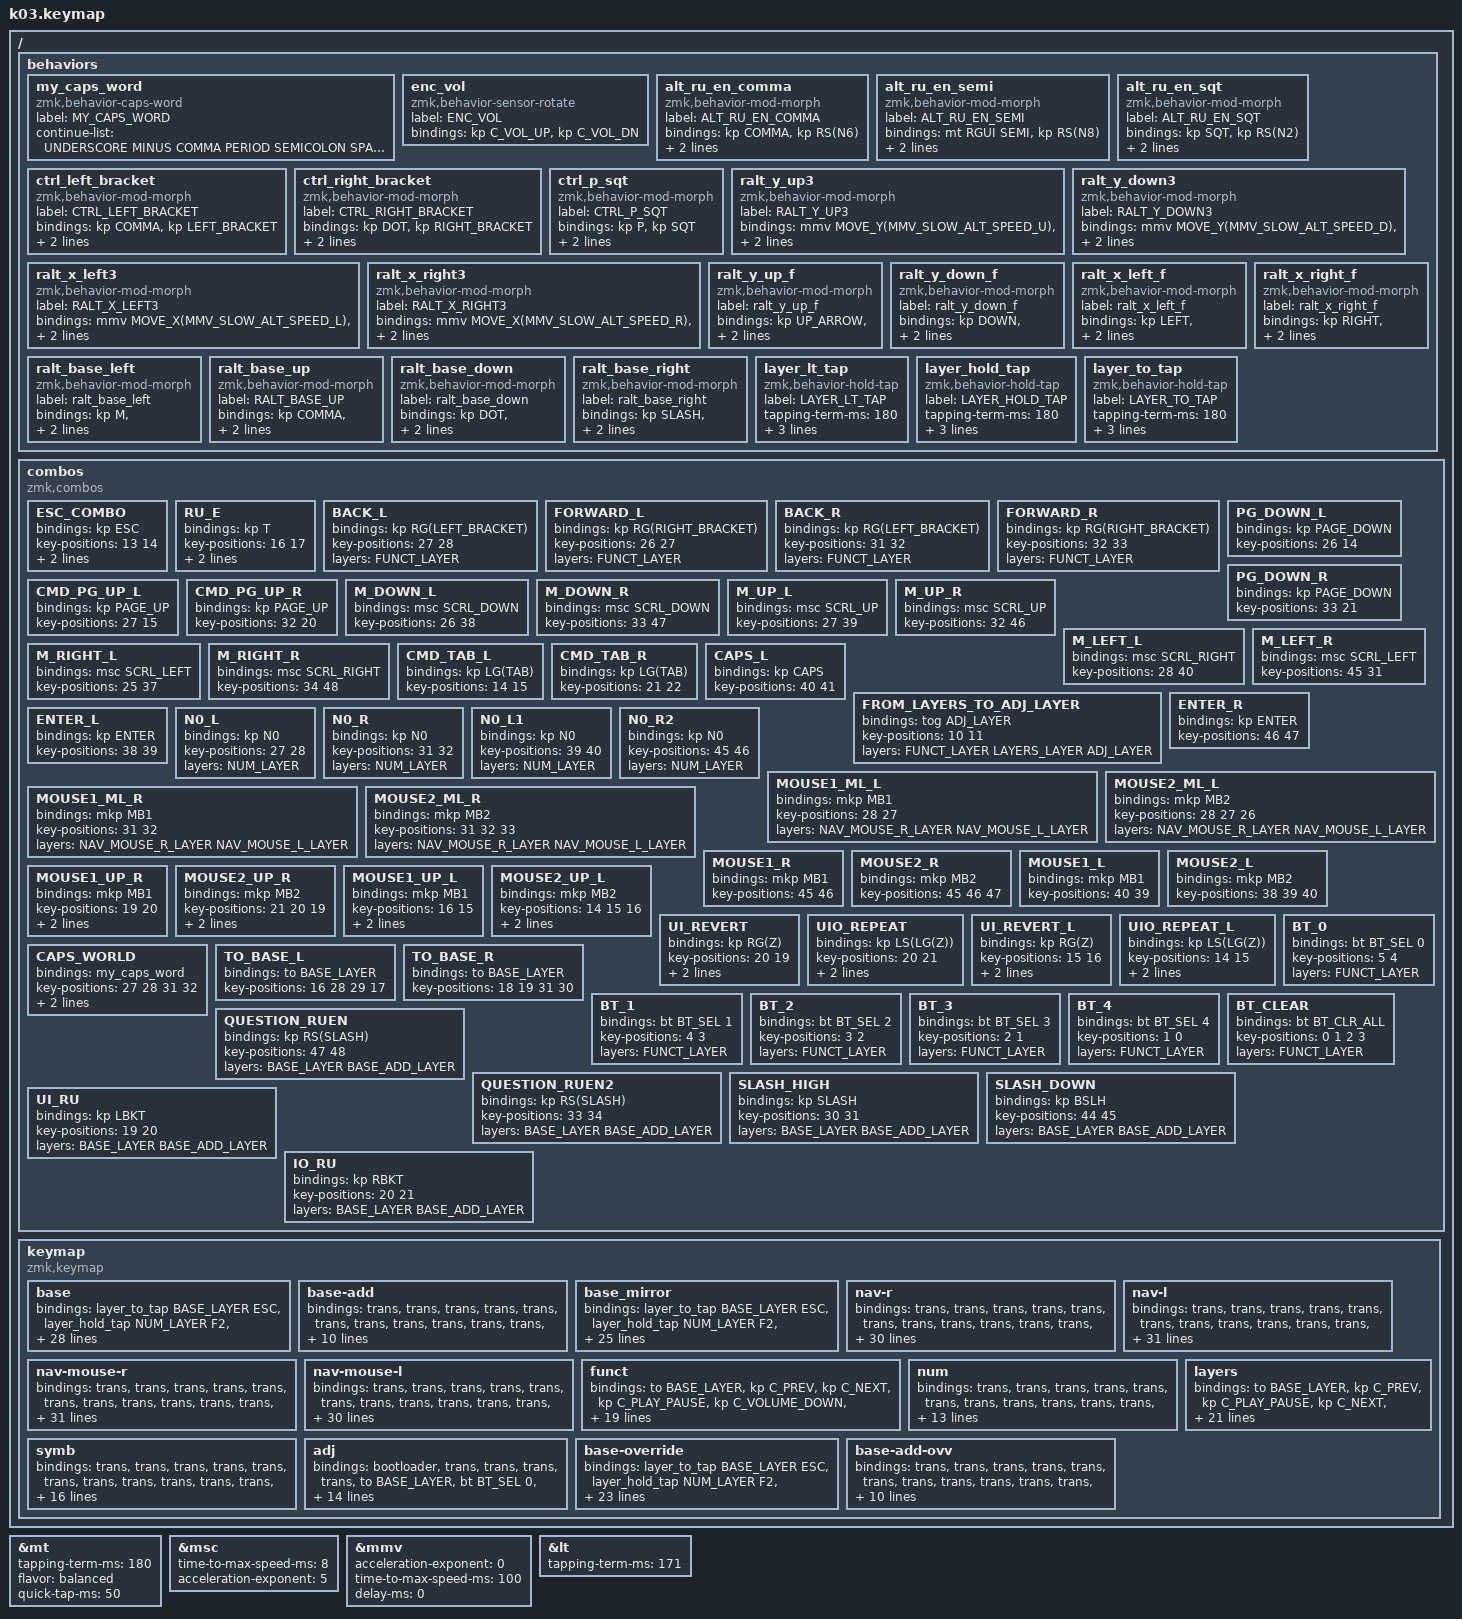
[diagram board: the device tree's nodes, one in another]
#define ZMK_POINTING_DEFAULT_SCRL_VAL 25

// Константы для перемещений

#define BASE_LAYER 0
#define BASE_ADD_LAYER 1
#define BASE_MIRROR_LAYER 2
#define NAV_R_LAYER 3
#define NAV_L_LAYER 4
#define NAV_MOUSE_R_LAYER 5
#define NAV_MOUSE_L_LAYER 6
#define FUNCT_LAYER 7
#define NUM_LAYER 8
#define SYMB_LAYER 9
#define LAYERS_LAYER 10
#define ADJ_LAYER 11
#define BASE_OVERRIDE_LAYER 12
#define BASE_ADD_OVERRIDE_LAYER 13

#define MMV_SLOW_ALT_SPEED 250
#define MMV_SLOW_ALT_SPEED_L -250
#define MMV_SLOW_ALT_SPEED_U -250
#define MMV_SLOW_ALT_SPEED_D 250
#define MMV_SLOW_ALT_SPEED_R 250

//

#define MMV_FAST_ALT_SPEED_X 950
#define MMV_FAST_ALT_SPEED_Y 950
#define MMV_FAST_ALT_SPEED_L -950
#define MMV_FAST_ALT_SPEED_U -950
#define MMV_FAST_ALT_SPEED_D 950
#define MMV_FAST_ALT_SPEED_R 950

//

#define MMV_FAST_SPEED_X 700
#define MMV_FAST_SPEED_Y 480
#define MMV_FAST_SPEED_L -MMV_FAST_SPEED_X
#define MMV_FAST_SPEED_U -MMV_FAST_SPEED_Y
#define MMV_FAST_SPEED_D MMV_FAST_SPEED_Y
#define MMV_FAST_SPEED_R MMV_FAST_SPEED_X

//
// 1100x750, 700x480, 600x410
#define MMV_SUPER_FAST_SPEED_X 1100
#define MMV_SUPER_FAST_SPEED_Y 750
#define MMV_SUPER_FAST_SPEED_L -MMV_SUPER_FAST_SPEED_X
#define MMV_SUPER_FAST_SPEED_U -MMV_SUPER_FAST_SPEED_Y
#define MMV_SUPER_FAST_SPEED_D MMV_SUPER_FAST_SPEED_Y
#define MMV_SUPER_FAST_SPEED_R MMV_SUPER_FAST_SPEED_X

#include <behaviors.dtsi>
#include <dt-bindings/zmk/bt.h>
#include <dt-bindings/zmk/keys.h>
#include <dt-bindings/zmk/outputs.h>
#include <dt-bindings/zmk/pointing.h>

&mt {
  tapping-term-ms = <180>;
  flavor = "balanced";
  quick-tap-ms = <50>;
};

&msc {
  time-to-max-speed-ms = <8>;
  acceleration-exponent = <5>;
};

&mmv {
  acceleration-exponent = <0>;
  time-to-max-speed-ms = <100>;
  delay-ms = <0>;
};

&lt {
  tapping-term-ms = <171>;
};

/ {
  behaviors {
     my_caps_word: my_caps_word {
        compatible = "zmk,behavior-caps-word";
        label = "MY_CAPS_WORD";
        #binding-cells = <0>;
        continue-list = <UNDERSCORE MINUS COMMA PERIOD SEMICOLON SPACE>;
     };
            
    enc_vol: enc_vol {
      compatible = "zmk,behavior-sensor-rotate";
      label = "ENC_VOL";
      #sensor-binding-cells = <0>;
      bindings = <&kp C_VOL_UP>, <&kp C_VOL_DN>;
    };
        
    // ru-б en/alt-ru ,
    alt_ru_en_comma: alt_ru_en_comma {
      compatible = "zmk,behavior-mod-morph";
      label = "ALT_RU_EN_COMMA";
      #binding-cells = <0>;
      bindings = <&kp COMMA>, <&kp RS(N6)>;
      mods = <(MOD_LALT | MOD_RALT)>;
      keep-mods = <(MOD_LCTL | MOD_RCTL)>;
    };

    // ru-ж en/alt-ru
    alt_ru_en_semi: alt_ru_en_semi {
      compatible = "zmk,behavior-mod-morph";
      label = "ALT_RU_EN_SEMI";
      #binding-cells = <0>;
      bindings = <&mt RGUI SEMI>, <&kp RS(N8)>;
      mods = <(MOD_LALT | MOD_RALT)>;
      keep-mods = <(MOD_LCTL | MOD_RCTL)>;
    };

    // ru-э en/alt-ru "
    alt_ru_en_sqt: alt_ru_en_sqt {
      compatible = "zmk,behavior-mod-morph";
      label = "ALT_RU_EN_SQT";
      #binding-cells = <0>;
      bindings = <&kp SQT>, <&kp RS(N2)>;
      mods = <(MOD_LALT | MOD_RALT)>;
      keep-mods = <(MOD_LCTL | MOD_RCTL)>;
    };                       

    ctrl_left_bracket: ctrl_left_bracket {
      compatible = "zmk,behavior-mod-morph";
      label = "CTRL_LEFT_BRACKET";
      #binding-cells = <0>;
      bindings = <&kp COMMA>, <&kp LEFT_BRACKET>;
      mods = <(MOD_LCTL | MOD_RCTL)>;
      keep-mods = <(MOD_LCTL | MOD_RCTL)>;
    };

    ctrl_right_bracket: ctrl_right_bracket {
      compatible = "zmk,behavior-mod-morph";
      label = "CTRL_RIGHT_BRACKET";
      #binding-cells = <0>;
      bindings = <&kp DOT>, <&kp RIGHT_BRACKET>;
      mods = <(MOD_LCTL | MOD_RCTL)>;
      keep-mods = <(MOD_LCTL | MOD_RCTL)>;
    };

    ctrl_p_sqt: ctrl_p_sqt {
      compatible = "zmk,behavior-mod-morph";
      label = "CTRL_P_SQT";
      #binding-cells = <0>;
      bindings = <&kp P>, <&kp SQT>;
      mods = <(MOD_LCTL | MOD_RCTL)>;
      keep-mods = <(MOD_LCTL | MOD_RCTL)>;
    };
    
    ralt_y_up3: ralt_y_up3 {
      compatible = "zmk,behavior-mod-morph";
      label = "RALT_Y_UP3";
      #binding-cells = <0>;
      bindings = 
        <&mmv MOVE_Y(MMV_SLOW_ALT_SPEED_U)>,
        <&mmv MOVE_Y(MMV_SUPER_FAST_SPEED_U)>;
      mods = <(MOD_RALT)>;
    };

    ralt_y_down3: ralt_y_down3 {
      compatible = "zmk,behavior-mod-morph";
      label = "RALT_Y_DOWN3";
      #binding-cells = <0>;
      bindings = 
        <&mmv MOVE_Y(MMV_SLOW_ALT_SPEED_D)>,
        <&mmv MOVE_Y(MMV_SUPER_FAST_SPEED_D)>;
      mods = <(MOD_RALT)>;
    };

    ralt_x_left3: ralt_x_left3 {
      compatible = "zmk,behavior-mod-morph";
      label = "RALT_X_LEFT3";
      #binding-cells = <0>;
      bindings =
        <&mmv MOVE_X(MMV_SLOW_ALT_SPEED_L)>,
        <&mmv MOVE_X(MMV_SUPER_FAST_SPEED_L)>;
      mods = <(MOD_RALT)>;
    };

    ralt_x_right3: ralt_x_right3 {
      compatible = "zmk,behavior-mod-morph";
      label = "RALT_X_RIGHT3";
      #binding-cells = <0>;
      bindings =
        <&mmv MOVE_X(MMV_SLOW_ALT_SPEED_R)>,
        <&mmv MOVE_X(MMV_SUPER_FAST_SPEED_R)>;
      mods = <(MOD_RALT)>;
    };
    
    /* */
    ralt_y_up_f: ralt_y_up_f {
          compatible = "zmk,behavior-mod-morph";
          label = "ralt_y_up_f";
          #binding-cells = <0>;
          bindings = 
            <&kp UP_ARROW>,
            <&mmv MOVE_Y(MMV_SUPER_FAST_SPEED_U)>;
          mods = <(MOD_RALT)>;
        };
    
        ralt_y_down_f: ralt_y_down_f {
          compatible = "zmk,behavior-mod-morph";
          label = "ralt_y_down_f";
          #binding-cells = <0>;
          bindings = 
            <&kp DOWN>,
            <&mmv MOVE_Y(MMV_SUPER_FAST_SPEED_D)>;
          mods = <(MOD_RALT)>;
        };
    
        ralt_x_left_f: ralt_x_left_f {
          compatible = "zmk,behavior-mod-morph";
          label = "ralt_x_left_f";
          #binding-cells = <0>;
          bindings =
            <&kp LEFT>,
            <&mmv MOVE_X(MMV_SUPER_FAST_SPEED_L)>;
          mods = <(MOD_RALT)>;
        };
    
        ralt_x_right_f: ralt_x_right_f {
          compatible = "zmk,behavior-mod-morph";
          label = "ralt_x_right_f";
          #binding-cells = <0>;
          bindings =
            <&kp RIGHT>,
            <&mmv MOVE_X(MMV_SUPER_FAST_SPEED_R)>;
          mods = <(MOD_RALT)>;
        };
    /* */

    /* mouse 0 layer */
    ralt_base_left: ralt_base_left {
      compatible = "zmk,behavior-mod-morph";
      label = "ralt_base_left";
      #binding-cells = <0>;
      bindings =
        <&kp M>,
        <&mmv MOVE_X(MMV_SUPER_FAST_SPEED_L)>;
      mods = <(MOD_RALT)>;
    };

    ralt_base_up: ralt_base_up {
      compatible = "zmk,behavior-mod-morph";
      label = "RALT_BASE_UP";
      #binding-cells = <0>;
      bindings = 
        <&kp COMMA>,
        <&mmv MOVE_Y(MMV_SUPER_FAST_SPEED_U)>;
      mods = <(MOD_RALT)>;
    };

    ralt_base_down: ralt_base_down {
      compatible = "zmk,behavior-mod-morph";
      label = "ralt_base_down";
      #binding-cells = <0>;
      bindings = 
        <&kp DOT>,
        <&mmv MOVE_Y(MMV_SUPER_FAST_SPEED_D)>;
      mods = <(MOD_RALT)>;
    };

    ralt_base_right: ralt_base_right {
      compatible = "zmk,behavior-mod-morph";
      label = "ralt_base_right";
      #binding-cells = <0>;
      bindings =
        <&kp SLASH>,
        <&mmv MOVE_X(MMV_SUPER_FAST_SPEED_R)>;
      mods = <(MOD_RALT)>;
    };
    /* end mouse 0 layer */

    layer_lt_tap: layer_lt_tap {
      compatible = "zmk,behavior-hold-tap";
      label = "LAYER_LT_TAP";
      #binding-cells = <2>;
      tapping-term-ms = <180>;
      quick-tap-ms = <0>;
      flavor = "tap-preferred";
      bindings = <&lt>, <&kp>;
    };

    layer_hold_tap: layer_hold_tap {
      compatible = "zmk,behavior-hold-tap";
      label = "LAYER_HOLD_TAP";
      #binding-cells = <2>;
      tapping-term-ms = <180>;
      quick-tap-ms = <0>;
      flavor = "tap-preferred";
      bindings = <&tog>, <&kp>;
    };

    layer_to_tap: layer_to_tap {
      compatible = "zmk,behavior-hold-tap";
      label = "LAYER_TO_TAP";
      #binding-cells = <2>;
      tapping-term-ms = <180>;
      quick-tap-ms = <0>;
      flavor = "tap-preferred";
      bindings = <&to>, <&kp>;
    };
  };

    combos {
        compatible = "zmk,combos";
        
         ESC_COMBO {
                    bindings = <&kp ESC>;
                    key-positions = <13 14>;
                    layers = <BASE_LAYER BASE_ADD_LAYER BASE_OVERRIDE_LAYER BASE_ADD_OVERRIDE_LAYER>;
                };
                
                  RU_E {
                                    bindings = <&kp T>;
                                    key-positions = <16 17>;
                                    layers = <BASE_LAYER BASE_ADD_LAYER BASE_OVERRIDE_LAYER BASE_ADD_OVERRIDE_LAYER>;
                                };
        
        BACK_L {
            bindings = <&kp RG(LEFT_BRACKET)>;
            key-positions = <27 28>;
            layers = <FUNCT_LAYER>;
        };
        
        FORWARD_L {
            bindings = <&kp RG(RIGHT_BRACKET)>;
            key-positions = <26 27>;
            layers = <FUNCT_LAYER>;
        };
        
        BACK_R {
            bindings = <&kp RG(LEFT_BRACKET)>;
            key-positions = <31 32>;
            layers = <FUNCT_LAYER>;
        };
                        
        FORWARD_R {
            bindings = <&kp RG(RIGHT_BRACKET)>;
            key-positions = <32 33>;
            layers = <FUNCT_LAYER>;
        };

        PG_DOWN_L {
            bindings = <&kp PAGE_DOWN>;
            key-positions = <26 14>;
        };

        PG_DOWN_R {
            bindings = <&kp PAGE_DOWN>;
            key-positions = <33 21>;
        };

        CMD_PG_UP_L {
            bindings = <&kp PAGE_UP>;
            key-positions = <27 15>;
        };

        CMD_PG_UP_R {
            bindings = <&kp PAGE_UP>;
            key-positions = <32 20>;
        };

        M_DOWN_L {
            bindings = <&msc SCRL_DOWN>;
            key-positions = <26 38>;
        };

        M_DOWN_R {
            bindings = <&msc SCRL_DOWN>;
            key-positions = <33 47>;
        };

        M_UP_L {
            bindings = <&msc SCRL_UP>;
            key-positions = <27 39>;
        };

        M_UP_R {
            bindings = <&msc SCRL_UP>;
            key-positions = <32 46>;
        };

        M_LEFT_L {
            bindings = <&msc SCRL_RIGHT>;
            key-positions = <28 40>;
        };

        M_LEFT_R {
            bindings = <&msc SCRL_LEFT>;
            key-positions = <45 31>;
        };

        M_RIGHT_L {
            bindings = <&msc SCRL_LEFT>;
            key-positions = <25 37>;
        };

        M_RIGHT_R {
            bindings = <&msc SCRL_RIGHT>;
            key-positions = <34 48>;
        };

        CMD_TAB_L {
            bindings = <&kp LG(TAB)>;
            key-positions = <14 15>;
        };

        CMD_TAB_R {
            bindings = <&kp LG(TAB)>;
            key-positions = <21 22>;
        };

        CAPS_L {
            bindings = <&kp CAPS>;
            key-positions = <40 41>;
        };       

        FROM_LAYERS_TO_ADJ_LAYER {
            bindings = <&tog ADJ_LAYER>;
            key-positions = <10 11>;
            layers = <FUNCT_LAYER LAYERS_LAYER ADJ_LAYER>;
        };

        ENTER_R {
            bindings = <&kp ENTER>;
            key-positions = <46 47>;
        };

        ENTER_L {
            bindings = <&kp ENTER>;
            key-positions = <38 39>;
        };

        N0_L {
            bindings = <&kp N0>;
            key-positions = <27 28>;
            layers = <NUM_LAYER>;
        };

        N0_R {
            bindings = <&kp N0>;
            key-positions = <31 32>;
            layers = <NUM_LAYER>;
        };

        N0_L1 {
            bindings = <&kp N0>;
            key-positions = <39 40>;
            layers = <NUM_LAYER>;
        };

        N0_R2 {
            bindings = <&kp N0>;
            key-positions = <45 46>;
            layers = <NUM_LAYER>;
        };
        
        MOUSE1_ML_L {
                    bindings = <&mkp MB1>;
                    key-positions = <28 27>;
                    layers = <NAV_MOUSE_R_LAYER NAV_MOUSE_L_LAYER>;
                };
        
                MOUSE2_ML_L {
                    bindings = <&mkp MB2>;
                    key-positions = <28 27 26>;
                    layers = <NAV_MOUSE_R_LAYER NAV_MOUSE_L_LAYER>;
                };
        
                MOUSE1_ML_R {
                    bindings = <&mkp MB1>;
                    key-positions = <31 32>;
                    layers = <NAV_MOUSE_R_LAYER NAV_MOUSE_L_LAYER>;
                };
        
                MOUSE2_ML_R {
                    bindings = <&mkp MB2>;
                    key-positions = <31 32 33>;
                    layers = <NAV_MOUSE_R_LAYER NAV_MOUSE_L_LAYER>;
                };


        MOUSE1_R {
            bindings = <&mkp MB1>;
            key-positions = <45 46>;
        };

        MOUSE2_R {
            bindings = <&mkp MB2>;
            key-positions = <45 46 47>;
        };

        MOUSE1_L {
            bindings = <&mkp MB1>;
            key-positions = <40 39>;
        };

        MOUSE2_L {
            bindings = <&mkp MB2>;
            key-positions = <38 39 40>;
        };

        MOUSE1_UP_R {
            bindings = <&mkp MB1>;
            key-positions = <19 20>;
            layers = <NAV_R_LAYER NAV_L_LAYER NAV_MOUSE_R_LAYER NAV_MOUSE_L_LAYER>;
        };

        MOUSE2_UP_R {
            bindings = <&mkp MB2>;
            key-positions = <21 20 19>;
            layers = <NAV_R_LAYER NAV_L_LAYER NAV_MOUSE_R_LAYER NAV_MOUSE_L_LAYER>;
        };

        MOUSE1_UP_L {
            bindings = <&mkp MB1>;
            key-positions = <16 15>;
            layers = <NAV_R_LAYER NAV_L_LAYER NAV_MOUSE_R_LAYER NAV_MOUSE_L_LAYER>;
        };

        MOUSE2_UP_L {
            bindings = <&mkp MB2>;
            key-positions = <14 15 16>;
            layers = <NAV_R_LAYER NAV_L_LAYER NAV_MOUSE_R_LAYER NAV_MOUSE_L_LAYER>;
        };

        UI_REVERT {
            bindings = <&kp RG(Z)>;
            key-positions = <20 19>;
            layers = <FUNCT_LAYER BASE_OVERRIDE_LAYER LAYERS_LAYER>;
        };

        UIO_REPEAT {
            bindings = <&kp LS(LG(Z))>;
            key-positions = <20 21>;
            layers = <FUNCT_LAYER BASE_OVERRIDE_LAYER LAYERS_LAYER>;
        };

        UI_REVERT_L {
            bindings = <&kp RG(Z)>;
            key-positions = <15 16>;
            layers = <FUNCT_LAYER BASE_OVERRIDE_LAYER LAYERS_LAYER>;
        };

        UIO_REPEAT_L {
            bindings = <&kp LS(LG(Z))>;
            key-positions = <14 15>;
            layers = <FUNCT_LAYER BASE_OVERRIDE_LAYER LAYERS_LAYER>;
        };

        CAPS_WORLD {
            bindings = <&my_caps_word>;
            key-positions = <27 28 31 32>;
            layers = <BASE_LAYER BASE_ADD_LAYER BASE_MIRROR_LAYER BASE_OVERRIDE_LAYER BASE_ADD_OVERRIDE_LAYER>;
        };
        
        TO_BASE_L {
                    bindings = <&to BASE_LAYER>;
                    key-positions = <16 28 29 17>;
                };
        
                TO_BASE_R {
                    bindings = <&to BASE_LAYER>;
                    key-positions = <18 19 31 30>;
                };
                
        BT_0 {
            bindings = <&bt BT_SEL 0>;
            key-positions = <5 4>;
            layers = <FUNCT_LAYER>;
        };

        BT_1 {
            bindings = <&bt BT_SEL 1>;
            key-positions = <4 3>;
            layers = <FUNCT_LAYER>;
        };

        BT_2 {
            bindings = <&bt BT_SEL 2>;
            key-positions = <3 2>;
            layers = <FUNCT_LAYER>;
        };

        BT_3 {
            bindings = <&bt BT_SEL 3>;
            key-positions = <2 1>;
            layers = <FUNCT_LAYER>;
        };

        BT_4 {
            bindings = <&bt BT_SEL 4>;
            key-positions = <1 0>;
            layers = <FUNCT_LAYER>;
        };

        BT_CLEAR {
            bindings = <&bt BT_CLR_ALL>;
            key-positions = <0 1 2 3>;
            layers = <FUNCT_LAYER>;
        };
         
         QUESTION_RUEN {
                           bindings = <&kp RS(SLASH)>;
                           key-positions = <47 48>;
                           layers = <BASE_LAYER BASE_ADD_LAYER>;
                        };
                        
                        QUESTION_RUEN2 {
                                                   bindings = <&kp RS(SLASH)>;
                                                   key-positions = <33 34>;
                                                   layers = <BASE_LAYER BASE_ADD_LAYER>;
                                                };
                                                
    SLASH_HIGH {
                                                       bindings = <&kp SLASH>;
                                                       key-positions = <30 31>;
                                                       layers = <BASE_LAYER BASE_ADD_LAYER>;
                                                    };
                                                                                      
                                                    SLASH_DOWN {
                                                                                                                                                   bindings = <&kp BSLH>;
                                                                                                                                                   key-positions = <44 45>;
                                                                                                                                                   layers = <BASE_LAYER BASE_ADD_LAYER>;
                                                                                                                                                };
                                                  
                        UI_RU {
                                                   bindings = <&kp LBKT>;
                                                   key-positions = <19 20>;
                                                   layers = <BASE_LAYER BASE_ADD_LAYER>;
                                                };
                        
                        IO_RU {
                                                   bindings = <&kp RBKT>;
                                                   key-positions = <20 21>;
                                                   layers = <BASE_LAYER BASE_ADD_LAYER>;
                                                };                      
    };

  keymap {
    compatible = "zmk,keymap";

    base {
      bindings = <
        /* base A L */
        &layer_to_tap BASE_LAYER ESC
        &layer_hold_tap NUM_LAYER F2
        &layer_hold_tap SYMB_LAYER F3
        &layer_hold_tap NAV_L_LAYER F4
        &layer_hold_tap FUNCT_LAYER F5
        &layer_hold_tap BASE_MIRROR_LAYER F6
        /* base A R */        
        &layer_hold_tap FUNCT_LAYER F7
        &layer_hold_tap NAV_R_LAYER F8       
        &layer_hold_tap NUM_LAYER F9
        &layer_hold_tap SYMB_LAYER F10
        &layer_to_tap BASE_MIRROR_LAYER F11
        &layer_to_tap BASE_LAYER F12

        /* base B L */
        &kp LG(TAB)
        &kp Q
        &kp W
        &kp E
        &kp R
        &kp T
        /* base B R */
        &kp Y
        &kp U
        &kp I
        &kp O
        &kp P
        &kp GRAVE        

        /* base C L */
        &my_caps_word
        &mt LGUI A
        &mt LCTRL S
        &mt LALT D
        &mt LSHFT F
        &lt BASE_ADD_LAYER G
        /* base C R */
        &lt BASE_ADD_LAYER H
        &mt RSHIFT J
        &mt RALT K
        &mt RCTRL L
        &mt RGUI SEMI
        &kp SLASH

        /* base D L */
        &none
        &lt BASE_ADD_LAYER Z
        &kp X
        &kp C
        &kp V
        &kp B
        &lt FUNCT_LAYER CAPS
        /* base D R */
        &lt FUNCT_LAYER SPACE
        &kp N
        &kp M
        &kp COMMA
        &kp DOT
        &lt BASE_ADD_LAYER SQT
        &kp BSLH

        /* base T L */
        &lt BASE_MIRROR_LAYER MINUS
        &lt NUM_LAYER EQUAL
        &lt SYMB_LAYER TAB
        &lt NAV_L_LAYER SPACE
        &lt FUNCT_LAYER DEL
        /* base T R */
        &lt FUNCT_LAYER ESC
        &lt NAV_R_LAYER RG(RC(SPACE))
        &lt NUM_LAYER BACKSPACE
        &lt SYMB_LAYER LBKT
        &lt BASE_MIRROR_LAYER RBKT
      >;
      display-name = "base";
    };
    
    base-add{
      bindings = <
        /* base-add A L */
        &trans
        &trans
        &trans
        &trans
        &trans
        &trans
        /* base-add A R */        
        &trans
        &trans
        &trans
        &trans
        &trans
        &trans

        /* base-add B L */
        &trans
        &trans          
        &trans
        &trans
        &trans
        &kp BSLH
        /* base-add B R */
        &trans
        &trans         
        &trans
        &trans                
        &kp GRAVE
        &trans        

        /* base-add C L */
        &trans
        &trans     
        &trans
        &trans
        &trans
        &trans
        /* base-add C R */
        &trans
        &trans
        &trans
        &trans        
        &kp SQT
        &trans
        
        /* base-add D L */
        &trans
        &trans
        &kp MINUS
        &kp EQUAL
        &trans
        &trans
        &trans
        /* base-add D R */
        &trans
        &trans
        &trans
        &kp LBKT
        &kp RBKT
        &kp BSLH
        &trans

        /* base-add T L */
        &trans
        &trans
        &trans
        &trans
        &trans
        &trans
        /* base-add T R */
        &trans
        &trans
        &trans
        &trans
        &trans
        &trans
      >;
      display-name = "base";
    };

    base_mirror {
      bindings = <
        /* base-m a l */
        &layer_to_tap BASE_LAYER ESC
                &layer_hold_tap NUM_LAYER F2
                &layer_hold_tap SYMB_LAYER F3
                &layer_hold_tap NAV_L_LAYER F4
                &layer_hold_tap FUNCT_LAYER F5
                &layer_to_tap BASE_LAYER F6
        /* base-m A R */
        &layer_to_tap BASE_LAYER F7
                &layer_hold_tap FUNCT_LAYER F8
                &layer_hold_tap NAV_R_LAYER F9
                &layer_hold_tap NUM_LAYER F10
                &layer_hold_tap SYMB_LAYER F11
                &layer_to_tap BASE_LAYER F12
      
              /* base-m B L */
                            &kp GRAVE
                            &kp P
                            &kp O
                            &kp I
                            &kp U
                            &kp Y
              /* base-m B R */
              &kp T
              &kp R
              &kp E
              &kp W
              &kp Q
              &kp LG(TAB)
              
              /* base-m C L */
              &kp SQT
              &mt LGUI SEMI
              &mt LCTRL L
              &mt LALT K
              &mt LSHFT J
              &kp H
              /* base-m C R */
              &kp G
              &mt RSHIFT F
              &mt RALT D
              &mt RCTRL S
              &mt RGUI A
              &kp CAPS
      
              /* base-m D L */
              &kp BSLH
              &kp SLASH
              &kp DOT
              &kp COMMA
              &kp M
              &kp N
              &trans
              /* base-m D R */
              &trans
              &kp B
              &kp V
              &kp C
              &kp X
              &kp Z
              &kp SPACE

              /* base-m T L */
              &lt SYMB_LAYER LBKT
              &lt LAYERS_LAYER RIGHT_BRACKET
              &lt NUM_LAYER BACKSPACE
              &lt NAV_R_LAYER RG(RC(SPACE))
              &lt FUNCT_LAYER ESC
              /* base-m T R */
              &lt FUNCT_LAYER DEL
              &lt NAV_L_LAYER SPACE
              &lt SYMB_LAYER TAB
              &lt LAYERS_LAYER MINUS
              &lt NUM_LAYER EQUAL                            
            >;
      display-name = "base-mirror";
    };

    nav-r {
      bindings = <
        /* nav-r A L */
        &trans
        &trans
        &trans
        &trans
        &trans
        &trans
        /* nav-r A R */
        &trans
        &trans
        &trans
        &trans
        &trans
        &trans

        /* nav-r B L */
        &trans
        &kp LEFT_ARROW
        &kp DOWN
        &kp UP
        &kp RIGHT_ARROW
        &tog NAV_R_LAYER
        /* nav-r B R */
        &tog NAV_R_LAYER
        &mmv MOVE_X(MMV_SLOW_ALT_SPEED_L)
                &mmv MOVE_Y(MMV_SLOW_ALT_SPEED_U)
                &mmv MOVE_Y(MMV_SLOW_ALT_SPEED_D)
                &mmv MOVE_X(MMV_SLOW_ALT_SPEED_R)
        &trans
        
        /* nav-r C L */        
        &kp LG(C)
        &kp LGUI
        &kp LCTRL
        &kp LALT
        &kp LSHFT
        &msc SCRL_UP
        /* nav-r C R */
        &msc SCRL_UP
        &kp LEFT_ARROW
        &kp UP
        &kp DOWN
        &kp RIGHT_ARROW
        &kp LG(C)

        /* nav-r D L */
        &kp RG(V)
        &mmv MOVE_X(MMV_SUPER_FAST_SPEED_L)
        &mmv MOVE_Y(MMV_SUPER_FAST_SPEED_D)
        &mmv MOVE_Y(MMV_SUPER_FAST_SPEED_U)
        &mmv MOVE_X(MMV_SUPER_FAST_SPEED_R)
        &msc SCRL_DOWN
        &trans
        /* nav-r D R */
        &trans
        &msc SCRL_DOWN
        &mmv MOVE_X(MMV_FAST_SPEED_L)
                &mmv MOVE_Y(MMV_FAST_SPEED_U)
                &mmv MOVE_Y(MMV_FAST_SPEED_D)        
                &mmv MOVE_X(MMV_FAST_SPEED_R)
        &kp LG(V)

        /* nav-r T L */
        &lt NAV_MOUSE_R_LAYER RG(LEFT_BRACKET)
        &lt NUM_LAYER RG(RIGHT_BRACKET)
        &lt SYMB_LAYER TAB
        &lt BASE_OVERRIDE_LAYER SPACE
        &lt FUNCT_LAYER DEL
        /* nav-r T R */
        &lt FUNCT_LAYER ESC
        &lt BASE_OVERRIDE_LAYER RG(RC(SPACE))
        &lt NUM_LAYER BACKSPACE
        &lt SYMB_LAYER RG(LEFT_BRACKET)
        &lt NAV_MOUSE_R_LAYER RG(RIGHT_BRACKET)
      >;
      display-name = "nav-r";
    };

nav-l {
  bindings = <
    /* nav-l A L */
    &trans
    &trans
    &trans
    &trans
    &trans
    &trans
    /* nav-l A R */
    &trans
    &trans
    &trans
    &trans
    &trans
    &trans

    /* nav-l B L */
    &trans
    &mmv MOVE_X(MMV_SLOW_ALT_SPEED_L)
    &mmv MOVE_Y(MMV_SLOW_ALT_SPEED_D)
    &mmv MOVE_Y(MMV_SLOW_ALT_SPEED_U)                    
    &mmv MOVE_X(MMV_SLOW_ALT_SPEED_R)
    &tog NAV_L_LAYER
    /* nav-l B R */
    &tog NAV_L_LAYER
    &kp LEFT_ARROW      
    &kp UP                      
    &kp DOWN
    &kp RIGHT_ARROW
    &trans
    /* nav-l C L */
    &kp LG(C)     
    &kp LEFT_ARROW
    &kp DOWN
    &kp UP
    &kp RIGHT_ARROW   
    &msc SCRL_UP
    /* nav-l C R */
    &msc SCRL_UP
    &kp LSHFT
    &kp LALT
    &kp LCTRL
    &kp LGUI
    &kp LG(C)

    /* nav-l D L */
    &kp LG(V)
    &mmv MOVE_X(MMV_SUPER_FAST_SPEED_L)
        &mmv MOVE_Y(MMV_SUPER_FAST_SPEED_D)
        &mmv MOVE_Y(MMV_SUPER_FAST_SPEED_U)                    
        &mmv MOVE_X(MMV_SUPER_FAST_SPEED_R)
    &msc SCRL_DOWN    
    &trans    
    /* nav-l D R */
    &trans
    &msc SCRL_DOWN
    &mmv MOVE_X(MMV_FAST_SPEED_L)
    &mmv MOVE_Y(MMV_FAST_SPEED_U)        
    &mmv MOVE_Y(MMV_FAST_SPEED_D)    
    &mmv MOVE_X(MMV_FAST_SPEED_R)
    &kp RG(V)
    /* nav-l T L */            
    &lt NAV_MOUSE_R_LAYER RG(LEFT_BRACKET)
    &lt NUM_LAYER RG(RIGHT_BRACKET)
    &lt SYMB_LAYER TAB
    &lt BASE_OVERRIDE_LAYER SPACE
    &lt FUNCT_LAYER DEL
    /* nav-l T R */
    &lt FUNCT_LAYER ESC
    &lt BASE_OVERRIDE_LAYER RG(RC(SPACE))
    &lt NUM_LAYER BACKSPACE
    &lt SYMB_LAYER RG(LEFT_BRACKET)
    &lt NAV_MOUSE_R_LAYER RG(RIGHT_BRACKET)
  >;
  display-name = "nav-l";
};

nav-mouse-r {
      bindings = <
              /* nav-m-r A L */
              &trans
              &trans
              &trans
              &trans
              &trans
              &trans
              /* nav-m-r A R */
              &trans
              &trans
              &trans
              &trans
              &trans
              &trans
      
              /* nav-m-r B L */
              &kp LG(TAB)
              &kp LEFT_ARROW
              &kp DOWN
              &kp UP
              &kp RIGHT_ARROW
              &tog NAV_MOUSE_R_LAYER              
              /* nav-m-r B R */
              &tog NAV_MOUSE_R_LAYER
              &kp LEFT_ARROW
              &kp UP
              &kp DOWN
              &kp RIGHT_ARROW
              &kp LG(TAB)
              /* nav-m-r C L */        
              &kp LG(C)
              &kp LGUI
              &kp LCTRL
              &kp LALT
              &kp LSHFT
              &msc SCRL_UP
              /* nav-m-r C R */
              &msc SCRL_UP
              &mmv MOVE_X(MMV_FAST_SPEED_L)
              &mmv MOVE_Y(MMV_FAST_SPEED_U)
              &mmv MOVE_Y(MMV_FAST_SPEED_D)        
              &mmv MOVE_X(MMV_FAST_SPEED_R)        
              &kp LG(C)
      
              /* nav-m-r D L */
              &kp RG(V)
              &mmv MOVE_X(MMV_SUPER_FAST_SPEED_L)
              &mmv MOVE_Y(MMV_SUPER_FAST_SPEED_D)
              &mmv MOVE_Y(MMV_SUPER_FAST_SPEED_U)
              &mmv MOVE_X(MMV_SUPER_FAST_SPEED_R)
              &msc SCRL_DOWN
              &trans
              /* nav-m-r D R */
              &trans
              &msc SCRL_DOWN
              &mmv MOVE_X(MMV_SLOW_ALT_SPEED_L)
                      &mmv MOVE_Y(MMV_SLOW_ALT_SPEED_U)
                      &mmv MOVE_Y(MMV_SLOW_ALT_SPEED_D)
                      &mmv MOVE_X(MMV_SLOW_ALT_SPEED_R)
              &kp LG(V)
      
              /* nav-m-r T L */
              &lt NAV_MOUSE_R_LAYER RG(LEFT_BRACKET)
              &lt NUM_LAYER RG(RIGHT_BRACKET)
              &lt SYMB_LAYER TAB
              &lt BASE_OVERRIDE_LAYER SPACE
              &lt FUNCT_LAYER DEL
              /* nav-m-r T R */
              &lt FUNCT_LAYER ESC
              &lt BASE_OVERRIDE_LAYER RG(RC(SPACE))
              &lt NUM_LAYER BACKSPACE
              &lt SYMB_LAYER RG(LEFT_BRACKET)
              &lt NAV_MOUSE_R_LAYER RG(RIGHT_BRACKET)
            >;
      display-name = "nav-mouse-r";
    };

nav-mouse-l {
  bindings = <
          /* nav-m-l A L */
          &trans
          &trans
          &trans
          &trans
          &trans
          &trans
          /* nav-m-l A R */
          &trans
          &trans
          &trans
          &trans
          &trans
          &trans
  
          /* nav-m-l B L */
          &kp LG(TAB)
                   &kp LEFT
                             &kp DOWN
                             &kp UP
                             &kp RIGHT
           &tog NAV_MOUSE_L_LAYER
          /* nav-m-l B R */
          &tog NAV_MOUSE_L_LAYER
          &kp LEFT_ARROW
          &kp UP
          &kp DOWN          
          &kp RIGHT_ARROW
          &kp LG(TAB)
                    
          /* nav-m-l C L */        
          &kp LG(C)
          &mmv MOVE_X(MMV_SUPER_FAST_SPEED_L)
                    &mmv MOVE_Y(MMV_SUPER_FAST_SPEED_D)
                    &mmv MOVE_Y(MMV_SUPER_FAST_SPEED_U)
                    &mmv MOVE_X(MMV_SUPER_FAST_SPEED_R) 
          &msc SCRL_UP
          /* nav-m-l C R */
          &msc SCRL_UP
          &kp LSHFT
          &kp LALT
                  &kp LCTRL                  
          &kp LGUI        
          &kp LG(C)
  
          /* nav-m-l D L */
          &kp RG(V)
          &mmv MOVE_X(MMV_SLOW_ALT_SPEED_L)
                                      &mmv MOVE_Y(MMV_SLOW_ALT_SPEED_U)
                                      &mmv MOVE_Y(MMV_SLOW_ALT_SPEED_D)
                                      &mmv MOVE_X(MMV_SLOW_ALT_SPEED_R)
          &msc SCRL_DOWN
          &trans
          /* nav-m-l D R */
          &trans
          &msc SCRL_DOWN
          &mmv MOVE_X(MMV_FAST_SPEED_L) 
                                        &mmv MOVE_Y(MMV_FAST_SPEED_U)
                                        &mmv MOVE_Y(MMV_FAST_SPEED_D)        
                                        &mmv MOVE_X(MMV_FAST_SPEED_R)
          &kp LG(V)
  
          /* nav-m-l T L */
          &lt NAV_MOUSE_R_LAYER RG(LEFT_BRACKET)
          &lt NUM_LAYER RG(RIGHT_BRACKET)
          &lt SYMB_LAYER TAB
          &lt BASE_OVERRIDE_LAYER SPACE
          &lt FUNCT_LAYER DEL
          /* nav-m-l T R */
          &lt FUNCT_LAYER ESC
          &lt BASE_OVERRIDE_LAYER RG(RC(SPACE))
          &lt NUM_LAYER BACKSPACE
          &lt SYMB_LAYER RG(LEFT_BRACKET)
          &lt NAV_MOUSE_R_LAYER RG(RIGHT_BRACKET)
        >;
  display-name = "nav-mouse-l";
};

    funct {
      bindings = <
        /* funct A L */
                &to BASE_LAYER
                &kp C_PREV                
                &kp C_NEXT
                &kp C_PLAY_PAUSE
                &kp C_VOLUME_DOWN
                &kp C_VOLUME_UP
        /* funct A R */        
        &kp C_VOLUME_DOWN
        &kp C_VOLUME_UP                        
                &kp F14
                &kp F15
                &kp C_PLAY_PAUSE                
                &to BASE_LAYER

        /* funct B L */
        &none
        &kp F3
        &kp F9
        &kp F8
        &kp F7
        &tog NAV_L_LAYER
        /* funct B R */
        &tog NAV_R_LAYER
        &kp F7
        &kp F8
        &kp F9
        &kp F3
        &none

        /* funct C L */
        &none
        &mt LGUI F2
        &mt LCTRL F6
        &mt LALT F5
        &mt LSHIFT F4
        &tog NAV_MOUSE_R_LAYER
        
        /* funct C R */
        &tog NAV_MOUSE_R_LAYER
        &mt RSHFT F4
        &mt RALT F5
        &mt RCTRL F6
        &mt RGUI F2
        &none

        /* funct D L */
        &none
        &kp F1
        &kp F12
        &kp F11
        &kp F10
        &kp LS(LA(L))
        &trans
        /* funct D R */
        &trans
        &kp LS(LA(L))
        &kp F10
        &kp F11
        &kp F12
        &kp F1
        &none

        /* funct T L */
        &none
        &mo NUM_LAYER
        &lt SYMB_LAYER TAB
        &lt BASE_OVERRIDE_LAYER SPACE
        &lt FUNCT_LAYER DEL
        /* funct T R */
        &lt FUNCT_LAYER ESC
        &lt BASE_OVERRIDE_LAYER RG(RC(SPACE))
        &lt NUM_LAYER BACKSPACE
        &mo SYMB_LAYER
        &none
      >;
      display-name = "funct";
    };

    num {
      bindings = <
        /* num A L */
        &trans
        &trans
        &trans
        &trans
        &trans
        &trans
        /* num A R */
        &trans
        &trans
        &trans
        &trans
        &trans
        &trans

        /* num B L */
        &kp RS(N8)
        &kp LS(MINUS)
        &kp N9
        &kp N8
        &kp N7
        &kp PLUS
        /* num B R */
        &kp PLUS
        &kp N7
        &kp N8
        &kp N9
        &kp RS(MINUS)
        &kp RS(N8)

        /* num C L */
        &kp DOT
        &mt LGUI N0
        &mt LCTRL N6
        &mt LALT N5
        &mt LSHFT N4
        &kp MINUS
        /* num C R */
        &kp MINUS
        &mt RSHIFT N4
        &mt RIGHT_ALT N5
        &mt RCTRL N6
        &mt RGUI N0
        &kp DOT

        /* num D L */
        &kp SLASH
        &kp BACKSLASH
        &kp N3
        &kp N2
        &kp N1
        &kp EQUAL
        &trans
        /* num D R */
        &trans
        &kp EQUAL
        &kp N1
        &kp N2
        &kp N3
        &kp SLASH
        &kp BACKSLASH

        /* num T L */
        &trans
        &trans
        &kp TAB
        &kp SPACE
        &kp DELETE
        /* num T R */
        &kp ESC
        &kp CAPSLOCK
        &kp BACKSPACE
        &trans
        &trans
      >;
      label = "num";
    };

    symb {
      bindings = <
        /* symb row 1 L */
        &trans
        &trans
        &trans
        &trans
        &trans
        &trans
        /* row 1 R */
        &trans
        &trans
        &trans
        &trans
        &trans
        &trans

        /* symb B L */
        &kp SQT
        &kp RS(N2)
        &kp RS(N4)
        &kp LEFT_PARENTHESIS
        &kp RIGHT_PARENTHESIS
        &kp RS(N3)
        /* symb B R */
        &kp RS(N3)
        &kp LEFT_PARENTHESIS
        &kp RIGHT_PARENTHESIS
        &kp RS(N4)
        &kp RS(N2)
        &kp SQT

        /* symb C L */
        &kp RS(SQT)
        &mt RGUI PLUS
        &mt RCTRL RS(MINUS)
        &mt RALT EQUAL
        &mt RSHFT MINUS
        &kp SLASH
        /* symb C R */
        &kp SLASH
        &mt RSHFT MINUS
        &mt RALT EQUAL
        &mt RCTRL RS(MINUS)
        &mt RGUI PLUS
        &kp RS(SQT)

        /* symb D L */
        &kp RS(N8)
        &kp RS(N7)
        &kp RS(N6)
        &kp RS(N5)
        &kp RS(N1)
        &kp BACKSLASH
        &trans
        /* symb D R */
        &trans
        &kp BACKSLASH
        &kp RS(N1)
        &kp RS(N5)
        &kp RS(N6)
        &kp RS(N7)
        &kp RS(N8)

        /* symb T L */
        &trans
        &trans
        &kp TAB
        &kp SPACE
        &kp DELETE
        /* symb T R */
        &kp ESC
        &kp CAPSLOCK
        &kp BACKSPACE
        &trans
        &trans
      >;
      label = "symb";
    };

    layers {
      bindings = <
        /* layers A L */
        &to BASE_LAYER
        &kp C_PREV
        &kp C_PLAY_PAUSE
        &kp C_NEXT
        &kp C_VOLUME_DOWN
        &kp C_VOLUME_UP
        /* layers A R */
        &kp F14
        &kp F15
        &kp F16
        &kp F17
        &kp F18
        &to BASE_LAYER

        /* layers B L */
        &to BASE_LAYER
        &kp C_PREV
        &kp C_PLAY_PAUSE
        &kp C_NEXT
        &kp C_VOLUME_DOWN
        &kp C_VOLUME_UP
        /* layers B R */
        &kp F14
        &kp F15
        &to BASE_LAYER
        &to BASE_LAYER
        &to BASE_LAYER
        &to BASE_LAYER

        /* layers C L */
        &to BASE_LAYER
        &to NUM_LAYER
        &to SYMB_LAYER
        &to NAV_L_LAYER
        &to FUNCT_LAYER
        &tog BASE_MIRROR_LAYER
        /* layers C R */
        &tog BASE_MIRROR_LAYER
        &to FUNCT_LAYER
        &to NAV_R_LAYER
        &to NUM_LAYER
        &to SYMB_LAYER
        &to BASE_LAYER

        /* layers D L */
        &to BASE_LAYER
        &kp LGUI
        &kp LCTRL
        &kp LALT
        &kp LSHFT
        &kp DELETE
        &trans
        /* layers D R */
        &trans
        &kp DELETE
        &kp RSHIFT
        &kp RALT
        &kp RCTRL
        &kp RGUI
        &to BASE_LAYER

        /* layers T L */
        &tog BASE_MIRROR_LAYER
        &tog NUM_LAYER
        &tog SYMB_LAYER
        &tog NAV_L_LAYER
        &tog FUNCT_LAYER
        /* layers T R */
        &tog FUNCT_LAYER
        &tog NAV_R_LAYER
        &tog NUM_LAYER
        &tog SYMB_LAYER
        &tog BASE_MIRROR_LAYER
      >;
      label = "layers";
    };

    adj {
      bindings = <
      
        /* adj A L */
        &bootloader
        &trans
        &trans
        &trans
        &trans
        &to BASE_LAYER
        /* adj A R */
        &bt BT_SEL 0
        &bt BT_SEL 1
        &bt BT_SEL 2
        &bt BT_SEL 3
        &bt BT_SEL 4
        &bt BT_CLR_ALL
        
        /* adj B L */
        &trans
        &trans
        &trans
        &trans
        &trans
        &trans
        /* adj B L */        
        &trans
        &trans
        &trans
        &trans
        &trans
        &studio_unlock
        
        /* adj C L */
        &trans
        &trans
        &trans
        &trans
        &trans
        &trans
        
        /* adj C R */
        &out OUT_BLE
        &kp C_VOL_DN
        &kp C_MUTE
        &kp C_VOL_UP
        &trans
        &trans
        /* adj C R */
        &to BASE_LAYER
        &trans
        &trans
        &trans
        &trans
        &trans
        
        /* layers D L */
        &trans
        &trans
        &out OUT_USB
        &kp C_PREV
        &kp C_PLAY_PAUSE
        &kp C_NEXT
        &trans
        /* layers D R */
        &to BASE_LAYER
        &trans
        &trans
        &trans
        &trans
        &trans
        &trans
        
        /* adj T L */
        &trans
        &trans
        &trans
        &trans
        &trans
        /* adj T R */
        &trans
        &trans
        &trans
        &trans
        &trans
      >;
      display-name = "Adjust";
    };

    base-override {
      bindings = <
        /* base-o A L */
                &layer_to_tap BASE_LAYER ESC
                &layer_hold_tap NUM_LAYER F2
                &layer_hold_tap SYMB_LAYER F3
                &layer_hold_tap NAV_L_LAYER F4
                &layer_hold_tap FUNCT_LAYER F5
                &layer_to_tap BASE_LAYER F6
                /* base-o A R */
                &layer_to_tap BASE_LAYER F7
                &layer_hold_tap FUNCT_LAYER F8
                &layer_hold_tap NAV_R_LAYER F9
                &layer_hold_tap NUM_LAYER F10
                &layer_hold_tap SYMB_LAYER F11
                &layer_to_tap BASE_LAYER F12

        /* base-o B L */
        &none
        &kp Q
        &kp W
        &kp E
        &kp R
        &kp T
        /* base-o B R */
        &kp Y
        &kp U
        &kp I
        &kp O
        &kp P
        &none

        /* base-o C L */
        &my_caps_word
        &mt LGUI A
        &mt LCTRL S
        &mt LALT D
        &mt LSHFT F
        &lt BASE_ADD_OVERRIDE_LAYER G
        /* base-o C R */
        &lt BASE_ADD_OVERRIDE_LAYER H
        &mt RSHIFT J
        &mt RALT K
        &mt RCTRL L
        &mt RGUI SEMI
        &none

        /* base-o D L */
        &none
        &lt BASE_ADD_OVERRIDE_LAYER Z
        &kp X
        &kp C
        &kp V
        &kp B
        &lt FUNCT_LAYER CAPS
        /* base-o D R */
        &lt FUNCT_LAYER SPACE
        &kp N
        &kp M
        &kp COMMA
        &kp DOT
        &lt BASE_ADD_OVERRIDE_LAYER SLASH
        &none

        /* base-o T L */
        &none
        &none
        &kp TAB
        &kp SPACE
        &kp DEL
        /* base-o T R */
        &kp ESC
        &kp CAPS
        &kp BACKSPACE
        &none
        &none
      >;
      display-name = "base-override";
    };
    
        base-add-ovv{
          bindings = <
            /* base-add-ovv A L */
            &trans
            &trans
            &trans
            &trans
            &trans
            &trans
            /* base-add-ovv A R */        
            &trans
            &trans
            &trans
            &trans
            &trans
            &trans
    
            /* base-add-ovv B L */
            &trans
            &trans
            &trans
            &trans
            &trans
            &kp BSLH
            /* base-add-ovv B R */
            &trans
            &trans
            &trans
            &trans
            &kp GRAVE
            &trans        
    
            /* base-add-ovv C L */
            &trans
            &trans
            &trans
            &trans
            &trans
            &trans
            /* base-add-ovv C R */
            &trans
            &trans
            &trans
            &trans
            &kp SQT
            &trans
            
            /* base-add-ovv D L */
            &trans
            &trans
            &kp MINUS
            &kp EQUAL
            &trans
            &trans
            &trans
            /* base-add-ovv D R */
            &trans
            &trans
            &trans
            &kp LBKT
            &kp RBKT
            &kp BSLH
            &trans
    
            /* base-add-ovv T L */
            &trans
            &trans
            &trans
            &trans
            &trans
            &trans
            /* base-add T R */
            &trans
            &trans
            &trans
            &trans
            &trans
            &trans
          >;
          display-name = "base-add-ovv";
        };
    
  };
};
